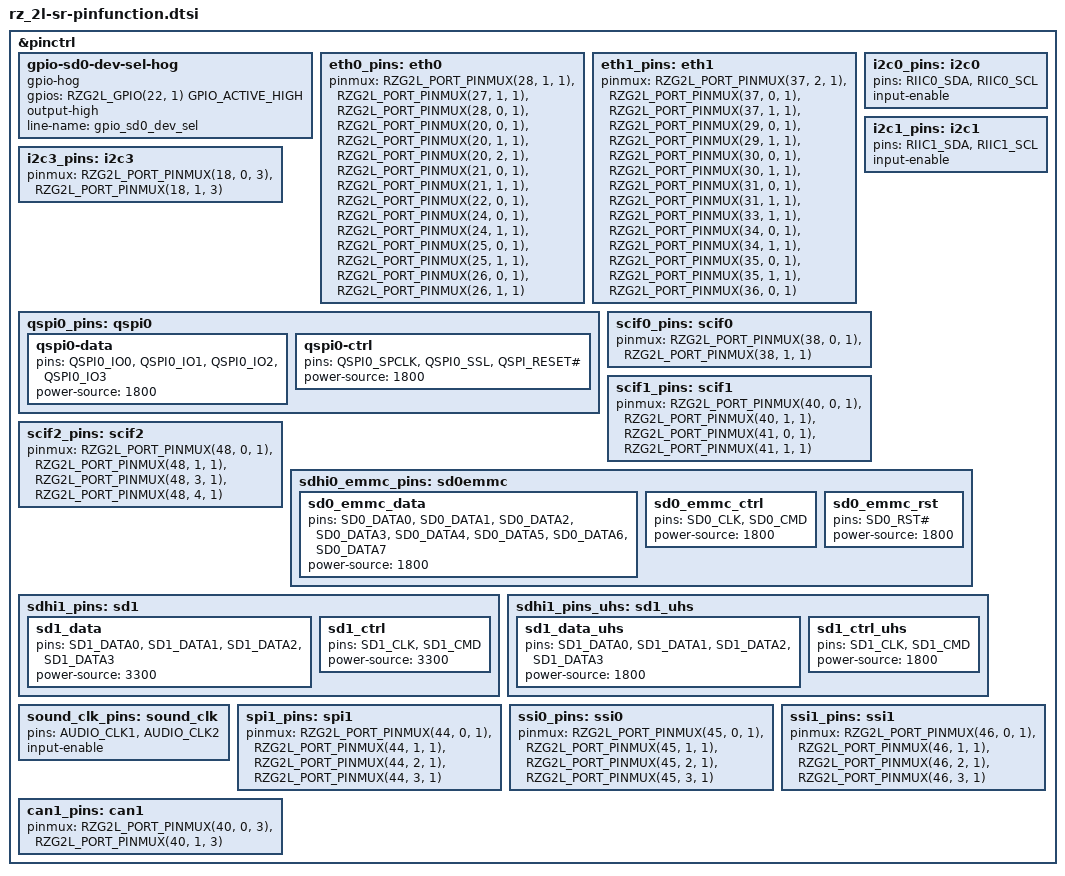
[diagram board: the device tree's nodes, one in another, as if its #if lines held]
// SPDX-License-Identifier: (GPL-2.0-only OR BSD-2-Clause)
/*
 * Device Tree Source for the RZ/V2L Solidrun SOM pincontrol parts
 *
 * Copyright (C) 2021 Renesas Electronics Corp.
 */

#include <dt-bindings/gpio/gpio.h>
#include <dt-bindings/pinctrl/rzg2l-pinctrl.h>

&pinctrl {
	pinctrl-names = "default";

	gpio-sd0-dev-sel-hog {
		gpio-hog;
		gpios = <RZG2L_GPIO(22, 1) GPIO_ACTIVE_HIGH>;
		output-high;
		line-name = "gpio_sd0_dev_sel";
	};

	eth0_pins: eth0 {
		pinmux = <RZG2L_PORT_PINMUX(28, 1, 1)>, /* ET0_LINKSTA */
			<RZG2L_PORT_PINMUX(27, 1, 1)>, /* ET0_MDC */
			<RZG2L_PORT_PINMUX(28, 0, 1)>, /* ET0_MDIO */
			<RZG2L_PORT_PINMUX(20, 0, 1)>, /* ET0_TXC */
			<RZG2L_PORT_PINMUX(20, 1, 1)>, /* ET0_TX_CTL */
			<RZG2L_PORT_PINMUX(20, 2, 1)>, /* ET0_TXD0 */
			<RZG2L_PORT_PINMUX(21, 0, 1)>, /* ET0_TXD1 */
			<RZG2L_PORT_PINMUX(21, 1, 1)>, /* ET0_TXD2 */
			<RZG2L_PORT_PINMUX(22, 0, 1)>, /* ET0_TXD3 */
			<RZG2L_PORT_PINMUX(24, 0, 1)>, /* ET0_RXC */
			<RZG2L_PORT_PINMUX(24, 1, 1)>, /* ET0_RX_CTL */
			<RZG2L_PORT_PINMUX(25, 0, 1)>, /* ET0_RXD0 */
			<RZG2L_PORT_PINMUX(25, 1, 1)>, /* ET0_RXD1 */
			<RZG2L_PORT_PINMUX(26, 0, 1)>, /* ET0_RXD2 */
			<RZG2L_PORT_PINMUX(26, 1, 1)>; /* ET0_RXD3 */
	};

	eth1_pins: eth1 {
		pinmux = <RZG2L_PORT_PINMUX(37, 2, 1)>, /* ET1_LINKSTA */
			<RZG2L_PORT_PINMUX(37, 0, 1)>, /* ET1_MDC */
			<RZG2L_PORT_PINMUX(37, 1, 1)>, /* ET1_MDIO */
			<RZG2L_PORT_PINMUX(29, 0, 1)>, /* ET1_TXC */
			<RZG2L_PORT_PINMUX(29, 1, 1)>, /* ET1_TX_CTL */
			<RZG2L_PORT_PINMUX(30, 0, 1)>, /* ET1_TXD0 */
			<RZG2L_PORT_PINMUX(30, 1, 1)>, /* ET1_TXD1 */
			<RZG2L_PORT_PINMUX(31, 0, 1)>, /* ET1_TXD2 */
			<RZG2L_PORT_PINMUX(31, 1, 1)>, /* ET1_TXD3 */
			<RZG2L_PORT_PINMUX(33, 1, 1)>, /* ET1_RXC */
			<RZG2L_PORT_PINMUX(34, 0, 1)>, /* ET1_RX_CTL */
			<RZG2L_PORT_PINMUX(34, 1, 1)>, /* ET1_RXD0 */
			<RZG2L_PORT_PINMUX(35, 0, 1)>, /* ET1_RXD1 */
			<RZG2L_PORT_PINMUX(35, 1, 1)>, /* ET1_RXD2 */
			<RZG2L_PORT_PINMUX(36, 0, 1)>; /* ET1_RXD3 */
	};

	i2c0_pins: i2c0 {
		pins = "RIIC0_SDA", "RIIC0_SCL";
		input-enable;
	};

	i2c1_pins: i2c1 {
		pins = "RIIC1_SDA", "RIIC1_SCL";
		input-enable;
	};

	i2c3_pins: i2c3 {
		pinmux = <RZG2L_PORT_PINMUX(18, 0, 3)>, /* SDA */
			 <RZG2L_PORT_PINMUX(18, 1, 3)>; /* SCL */
	};

	qspi0_pins: qspi0 {
		qspi0-data {
			pins = "QSPI0_IO0", "QSPI0_IO1", "QSPI0_IO2", "QSPI0_IO3";
			power-source = <1800>;
		};

		qspi0-ctrl {
			pins = "QSPI0_SPCLK", "QSPI0_SSL", "QSPI_RESET#";
			power-source = <1800>;
		};
	};

	scif0_pins: scif0 {
		pinmux = <RZG2L_PORT_PINMUX(38, 0, 1)>,	/* TxD */
			 <RZG2L_PORT_PINMUX(38, 1, 1)>;	/* RxD */
	};

	scif1_pins: scif1 {
		pinmux = <RZG2L_PORT_PINMUX(40, 0, 1)>, /* TxD */
			 <RZG2L_PORT_PINMUX(40, 1, 1)>, /* RxD */
			 <RZG2L_PORT_PINMUX(41, 0, 1)>, /* CTS# */
			 <RZG2L_PORT_PINMUX(41, 1, 1)>; /* RTS# */
	};

	scif2_pins: scif2 {
		pinmux = <RZG2L_PORT_PINMUX(48, 0, 1)>, /* TxD */
			 <RZG2L_PORT_PINMUX(48, 1, 1)>, /* RxD */
			 <RZG2L_PORT_PINMUX(48, 3, 1)>, /* CTS# */
			 <RZG2L_PORT_PINMUX(48, 4, 1)>; /* RTS# */
	};

#if SW_SD0_DEV_SEL
	sdhi0_emmc_pins: sd0emmc {
		sd0_emmc_data {
			pins = "SD0_DATA0", "SD0_DATA1", "SD0_DATA2", "SD0_DATA3",
				   "SD0_DATA4", "SD0_DATA5", "SD0_DATA6", "SD0_DATA7";
			power-source = <1800>;
		};

		sd0_emmc_ctrl {
			pins = "SD0_CLK", "SD0_CMD";
			power-source = <1800>;
		};

		sd0_emmc_rst {
			pins = "SD0_RST#";
			power-source = <1800>;
		};
	};
#else
	sdhi0_pins: sd0 {
		sd0_data {
			pins = "SD0_DATA0", "SD0_DATA1", "SD0_DATA2", "SD0_DATA3";
			power-source = <3300>;
		};

		sd0_ctrl {
			pins = "SD0_CLK", "SD0_CMD";
			power-source = <3300>;
		};
	};

	sdhi0_pins_uhs: sd0_uhs {
		sd0_data_uhs {
			pins = "SD0_DATA0", "SD0_DATA1", "SD0_DATA2", "SD0_DATA3";
			power-source = <1800>;
		};

		sd0_ctrl_uhs {
			pins = "SD0_CLK", "SD0_CMD";
			power-source = <1800>;
		};
	};
#endif

	sdhi1_pins: sd1 {
		sd1_data {
			pins = "SD1_DATA0", "SD1_DATA1", "SD1_DATA2", "SD1_DATA3";
			power-source = <3300>;
		};

		sd1_ctrl {
			pins = "SD1_CLK", "SD1_CMD";
			power-source = <3300>;
		};
	};

	sdhi1_pins_uhs: sd1_uhs {
		sd1_data_uhs {
			pins = "SD1_DATA0", "SD1_DATA1", "SD1_DATA2", "SD1_DATA3";
			power-source = <1800>;
		};

		sd1_ctrl_uhs {
			pins = "SD1_CLK", "SD1_CMD";
			power-source = <1800>;
		};
	};

	sound_clk_pins: sound_clk {
		pins = "AUDIO_CLK1", "AUDIO_CLK2";
		input-enable;
	};

	spi1_pins: spi1 {
		pinmux = <RZG2L_PORT_PINMUX(44, 0, 1)>, /* CK */
			 <RZG2L_PORT_PINMUX(44, 1, 1)>, /* MOSI */
			 <RZG2L_PORT_PINMUX(44, 2, 1)>, /* MISO */
			 <RZG2L_PORT_PINMUX(44, 3, 1)>; /* SSL */
	};

	ssi0_pins: ssi0 {
		pinmux = <RZG2L_PORT_PINMUX(45, 0, 1)>, /* BCK */
			 <RZG2L_PORT_PINMUX(45, 1, 1)>, /* RCK */
			 <RZG2L_PORT_PINMUX(45, 2, 1)>, /* TXD */
			 <RZG2L_PORT_PINMUX(45, 3, 1)>; /* RXD */
	};

	ssi1_pins: ssi1 {
		pinmux = <RZG2L_PORT_PINMUX(46, 0, 1)>, /* BCK */
			 <RZG2L_PORT_PINMUX(46, 1, 1)>, /* RCK */
			 <RZG2L_PORT_PINMUX(46, 2, 1)>, /* TXD */
			 <RZG2L_PORT_PINMUX(46, 3, 1)>; /* RXD */
	};

    can1_pins: can1 {
		pinmux = <RZG2L_PORT_PINMUX(40, 0, 3)>, /* TxD */
			<RZG2L_PORT_PINMUX(40, 1, 3)>; /* RxD */
	};
};

